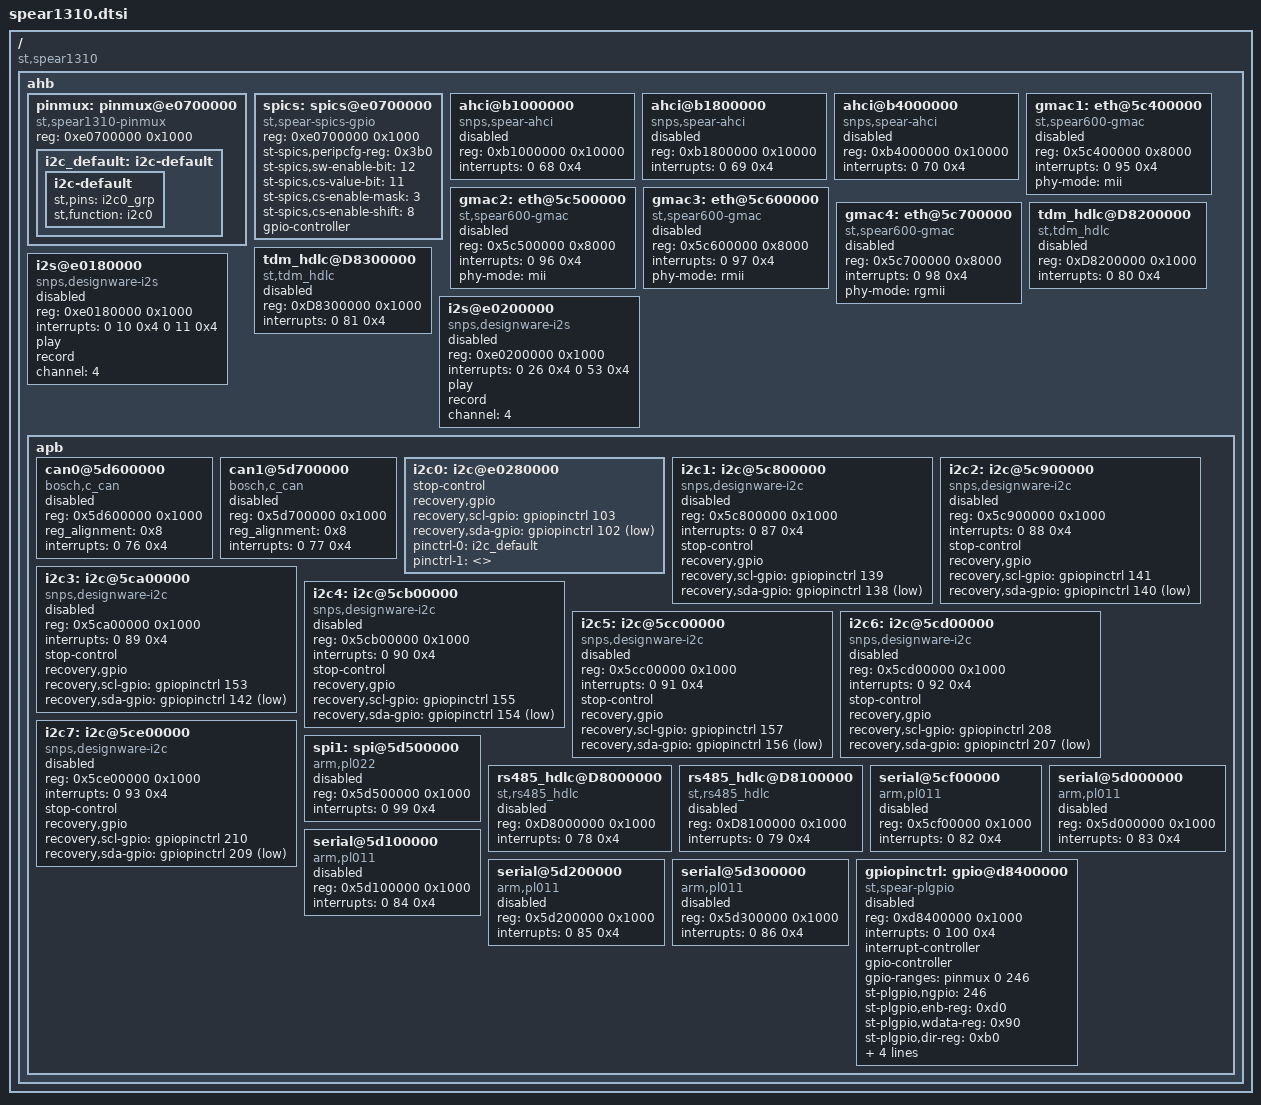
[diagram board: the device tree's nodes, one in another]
/*
 * DTS file for all SPEAr1310 SoCs
 *
 * Copyright 2012 Viresh Kumar <viresh.linux@gmail.com>
 *
 * The code contained herein is licensed under the GNU General Public
 * License. You may obtain a copy of the GNU General Public License
 * Version 2 or later at the following locations:
 *
 * http://www.opensource.org/licenses/gpl-license.html
 * http://www.gnu.org/copyleft/gpl.html
 */

/include/ "spear13xx.dtsi"

/ {
	compatible = "st,spear1310";

	ahb {
		pinmux: pinmux@e0700000{
			compatible = "st,spear1310-pinmux";
			reg = <0xe0700000 0x1000>;
			#gpio-range-cells = <2>;

			i2c_default: i2c-default {
				i2c-default {
					st,pins = "i2c0_grp";
					st,function = "i2c0";
				};
			};
		};

		spics: spics@e0700000{
			compatible = "st,spear-spics-gpio";
			reg = <0xe0700000 0x1000>;
			st-spics,peripcfg-reg = <0x3b0>;
			st-spics,sw-enable-bit = <12>;
			st-spics,cs-value-bit = <11>;
			st-spics,cs-enable-mask = <3>;
			st-spics,cs-enable-shift = <8>;
			gpio-controller;
			#gpio-cells = <2>;
		};

		ahci@b1000000 {
			compatible = "snps,spear-ahci";
			reg = <0xb1000000 0x10000>;
			interrupts = <0 68 0x4>;
			status = "disabled";
		};

		ahci@b1800000 {
			compatible = "snps,spear-ahci";
			reg = <0xb1800000 0x10000>;
			interrupts = <0 69 0x4>;
			status = "disabled";
		};

		ahci@b4000000 {
			compatible = "snps,spear-ahci";
			reg = <0xb4000000 0x10000>;
			interrupts = <0 70 0x4>;
			status = "disabled";
		};

		gmac1: eth@5c400000 {
			compatible = "st,spear600-gmac";
			reg = <0x5c400000 0x8000>;
			interrupts = <0 95 0x4>;
			interrupt-names = "macirq";
			phy-mode = "mii";
			status = "disabled";
		};

		gmac2: eth@5c500000 {
			compatible = "st,spear600-gmac";
			reg = <0x5c500000 0x8000>;
			interrupts = <0 96 0x4>;
			interrupt-names = "macirq";
			phy-mode = "mii";
			status = "disabled";
		};

		gmac3: eth@5c600000 {
			compatible = "st,spear600-gmac";
			reg = <0x5c600000 0x8000>;
			interrupts = <0 97 0x4>;
			interrupt-names = "macirq";
			phy-mode = "rmii";
			status = "disabled";
		};

		gmac4: eth@5c700000 {
			compatible = "st,spear600-gmac";
			reg = <0x5c700000 0x8000>;
			interrupts = <0 98 0x4>;
			interrupt-names = "macirq";
			phy-mode = "rgmii";
			status = "disabled";
		};

		tdm_hdlc@D8200000 {
			compatible = "st,tdm_hdlc";
			reg = <0xD8200000 0x1000>;
			interrupts = <0 80 0x4>;
			status = "disabled";
		};

		tdm_hdlc@D8300000 {
			compatible = "st,tdm_hdlc";
			reg = <0xD8300000 0x1000>;
			interrupts = <0 81 0x4>;
			status = "disabled";
		};

		i2s@e0180000 {
				compatible = "snps,designware-i2s";
				reg = <0xe0180000 0x1000>;
				interrupt-names = "play_irq", "record_irq";
				interrupts = <0 10 0x4
					      0 11 0x4 >;
				play;
				record;
				channel = <4>;
				status = "disabled";
			};

		i2s@e0200000 {
				compatible = "snps,designware-i2s";
				reg = <0xe0200000 0x1000>;
				interrupt-names = "play_irq", "record_irq";
				interrupts = <0 26 0x4
					      0 53 0x4>;
				play;
				record;
				channel = <4>;
				status = "disabled";
			};

		apb {
			can0@5d600000 {
				compatible = "bosch,c_can";
				reg = <0x5d600000 0x1000>;
				reg_alignment = <0x8>;
				interrupts = <0 76 0x4>;
				status = "disabled";
			};

			can1@5d700000 {
				compatible = "bosch,c_can";
				reg = <0x5d700000 0x1000>;
				reg_alignment = <0x8>;
				interrupts = <0 77 0x4>;
				status = "disabled";
			};

			i2c0: i2c@e0280000 {
				stop-control;
				recovery,gpio;
				recovery,scl-gpio = <&gpiopinctrl 103 0>;
				recovery,sda-gpio = <&gpiopinctrl 102 1>;
				pinctrl-names = "default", "sleep";
				pinctrl-0 = <&i2c_default>;
				pinctrl-1 = <>;
			};

			i2c1: i2c@5c800000 {
				#address-cells = <1>;
				#size-cells = <0>;
				compatible = "snps,designware-i2c";
				reg = <0x5c800000 0x1000>;
				interrupts = <0 87 0x4>;
				stop-control;
				recovery,gpio;
				recovery,scl-gpio = <&gpiopinctrl 139 0>;
				recovery,sda-gpio = <&gpiopinctrl 138 1>;
				status = "disabled";
			};

			i2c2: i2c@5c900000 {
				#address-cells = <1>;
				#size-cells = <0>;
				compatible = "snps,designware-i2c";
				reg = <0x5c900000 0x1000>;
				interrupts = <0 88 0x4>;
				stop-control;
				recovery,gpio;
				recovery,scl-gpio = <&gpiopinctrl 141 0>;
				recovery,sda-gpio = <&gpiopinctrl 140 1>;
				status = "disabled";
			};

			i2c3: i2c@5ca00000 {
				#address-cells = <1>;
				#size-cells = <0>;
				compatible = "snps,designware-i2c";
				reg = <0x5ca00000 0x1000>;
				interrupts = <0 89 0x4>;
				stop-control;
				recovery,gpio;
				recovery,scl-gpio = <&gpiopinctrl 153 0>;
				recovery,sda-gpio = <&gpiopinctrl 142 1>;
				status = "disabled";
			};

			i2c4: i2c@5cb00000 {
				#address-cells = <1>;
				#size-cells = <0>;
				compatible = "snps,designware-i2c";
				reg = <0x5cb00000 0x1000>;
				interrupts = <0 90 0x4>;
				stop-control;
				recovery,gpio;
				recovery,scl-gpio = <&gpiopinctrl 155 0>;
				recovery,sda-gpio = <&gpiopinctrl 154 1>;
				status = "disabled";
			};

			i2c5: i2c@5cc00000 {
				#address-cells = <1>;
				#size-cells = <0>;
				compatible = "snps,designware-i2c";
				reg = <0x5cc00000 0x1000>;
				interrupts = <0 91 0x4>;
				stop-control;
				recovery,gpio;
				recovery,scl-gpio = <&gpiopinctrl 157 0>;
				recovery,sda-gpio = <&gpiopinctrl 156 1>;
				status = "disabled";
			};

			i2c6: i2c@5cd00000 {
				#address-cells = <1>;
				#size-cells = <0>;
				compatible = "snps,designware-i2c";
				reg = <0x5cd00000 0x1000>;
				interrupts = <0 92 0x4>;
				stop-control;
				recovery,gpio;
				recovery,scl-gpio = <&gpiopinctrl 208 0>;
				recovery,sda-gpio = <&gpiopinctrl 207 1>;
				status = "disabled";
			};

			i2c7: i2c@5ce00000 {
				#address-cells = <1>;
				#size-cells = <0>;
				compatible = "snps,designware-i2c";
				reg = <0x5ce00000 0x1000>;
				interrupts = <0 93 0x4>;
				stop-control;
				recovery,gpio;
				recovery,scl-gpio = <&gpiopinctrl 210 0>;
				recovery,sda-gpio = <&gpiopinctrl 209 1>;
				status = "disabled";
			};

			spi1: spi@5d500000 {
				compatible = "arm,pl022", "arm,primecell";
				reg = <0x5d500000 0x1000>;
				interrupts = <0 99 0x4>;
				#address-cells = <1>;
				#size-cells = <0>;
				status = "disabled";
			};

			rs485_hdlc@D8000000 {
				compatible = "st,rs485_hdlc";
				reg = <0xD8000000 0x1000>;
				interrupts = <0 78 0x4>;
				status = "disabled";
			};

			rs485_hdlc@D8100000 {
				compatible = "st,rs485_hdlc";
				reg = <0xD8100000 0x1000>;
				interrupts = <0 79 0x4>;
				status = "disabled";
			};

			serial@5cf00000 {
				compatible = "arm,pl011", "arm,primecell";
				reg = <0x5cf00000 0x1000>;
				interrupts = <0 82 0x4>;
				status = "disabled";
			};

			serial@5d000000 {
				compatible = "arm,pl011", "arm,primecell";
				reg = <0x5d000000 0x1000>;
				interrupts = <0 83 0x4>;
				status = "disabled";
			};

			serial@5d100000 {
				compatible = "arm,pl011", "arm,primecell";
				reg = <0x5d100000 0x1000>;
				interrupts = <0 84 0x4>;
				status = "disabled";
			};

			serial@5d200000 {
				compatible = "arm,pl011", "arm,primecell";
				reg = <0x5d200000 0x1000>;
				interrupts = <0 85 0x4>;
				status = "disabled";
			};

			serial@5d300000 {
				compatible = "arm,pl011", "arm,primecell";
				reg = <0x5d300000 0x1000>;
				interrupts = <0 86 0x4>;
				status = "disabled";
			};

			gpiopinctrl: gpio@d8400000 {
				compatible = "st,spear-plgpio";
				reg = <0xd8400000 0x1000>;
				interrupts = <0 100 0x4>;
				#interrupt-cells = <1>;
				interrupt-controller;
				gpio-controller;
				#gpio-cells = <2>;
				gpio-ranges = <&pinmux 0 246>;
				status = "disabled";

				st-plgpio,ngpio = <246>;
				st-plgpio,enb-reg = <0xd0>;
				st-plgpio,wdata-reg = <0x90>;
				st-plgpio,dir-reg = <0xb0>;
				st-plgpio,ie-reg = <0x30>;
				st-plgpio,rdata-reg = <0x70>;
				st-plgpio,mis-reg = <0x10>;
				st-plgpio,eit-reg = <0x50>;
			};
		};
	};
};
